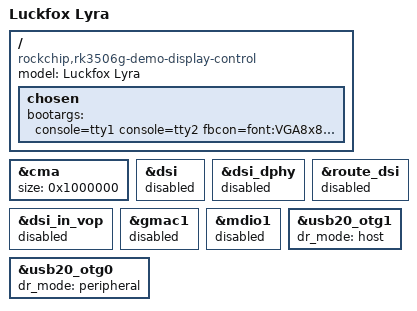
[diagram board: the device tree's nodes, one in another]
// SPDX-License-Identifier: (GPL-2.0+ OR MIT)
/*
 * Copyright (c) 2024 Rockchip Electronics Co., Ltd.
 */

/dts-v1/;

#include "rk3506-luckfox-lyra.dtsi"

/ {
	model = "Luckfox Lyra";
	compatible = "rockchip,rk3506g-demo-display-control", "rockchip,rk3506";

	chosen {
		bootargs = "console=tty1 console=tty2 fbcon=font:VGA8x8 storagemedia=sd root=/dev/mmcblk0p3 rootfstype=ext4 rootwait snd_aloop.index=7 snd_aloop.use_raw_jiffies=1";
	};
};

/**********display**********/
&cma {
	size = <0x1000000>;
};

&dsi {
	status = "disabled";
};

&dsi_dphy {
	status = "disabled";
};

&dsi_in_vop {
	status = "disabled";
};

&route_dsi {
	status = "disabled";
};

/**********ethernet**********/
&gmac1 {
	status = "disabled";
};

&mdio1 {
	status = "disabled";
};

/**********usb**********/
&usb20_otg0 {
	dr_mode = "peripheral";
	status = "okay";
};

&usb20_otg1 {
	dr_mode = "host";
	status = "okay";
};
